# AVR16EB14 register map
Vendor: Atmel; File version: 1.0
CPU: other r0p0, little endian, no MPU, no FPU, 4 interrupt priority bits
Registers are 8-bit, read-write, reset 0x0 unless marked. A register's access mark holds for its fields unless they carry their own. Offsets are from the block's base; [hi:lo] are bit positions; {n}, {i} and the like mark numbered series; 'fields as' and 'values as' point back to an identical list.

## BOD — Bod interface
Base 0x008000A0
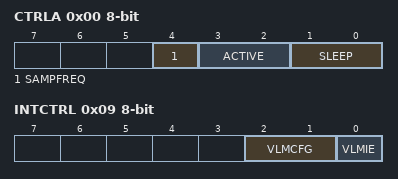
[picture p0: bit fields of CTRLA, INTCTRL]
0x00 CTRLA — Control A
  [4] SAMPFREQ ro — Sample frequency
    0=128HZ (Sampling frequency is 128 Hz); 1=32HZ (Sample frequency is 32 Hz)
  [3:2] ACTIVE ro — Operation in active mode
    0=DISABLE (Disabled); 1=ENABLED (Enabled in continuous mode); 2=SAMPLED (Enabled in sampled mode); 3=ENABLEWAIT (Enabled in continuous mode. Execution halted at wake-up until BOD is running)
  [1:0] SLEEP — Operation in sleep mode
    0=DISABLE (Disabled); 1=ENABLE (Enabled in continuous mode); 2=SAMPLE (Enabled in sampled mode)
0x01 CTRLB ro — Control B
  [2:0] LVL — Bod level
    0=BODLEVEL0 (BOD Disabled during normal operation); 1=BODLEVEL1 (1.9 V); 2=BODLEVEL2 (2.7 V); 3=BODLEVEL3 (4.5 V)
0x08 VLMCTRLA — Voltage level monitor Control
  [1:0] VLMLVL — voltage level monitor level
    0=OFF (VLM Disabled); 1=5ABOVE (VLM threshold 5% above BOD level); 2=15ABOVE (VLM threshold 15% above BOD level); 3=25ABOVE (VLM threshold 25% above BOD level)
0x09 INTCTRL — Voltage level monitor interrupt Control
  [2:1] VLMCFG — Configuration
    0=FALLING (VDD falls below VLM threshold); 1=RISING (VDD rises above VLM threshold); 2=BOTH (VDD crosses VLM threshold)
  [0] VLMIE — voltage level monitor interrrupt enable
0x0A INTFLAGS — Voltage level monitor interrupt Flags
  [0] VLMIF — Voltage level monitor interrupt flag
0x0B STATUS — Voltage level monitor status
  [0] VLMS ro
    0=ABOVE (The voltage is above the VLM threshold level); 1=BELOW (The voltage is below the VLM threshold level)

## BOOTROW
Base 0x00801100
0x00 BOOTROW

## USERROW
Base 0x00801200
Registers as BOOTROW (with BOOTROW read as USERROW).

## CCL — Configurable Custom Logic
Base 0x008001C0
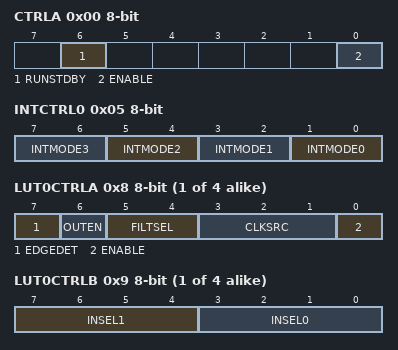
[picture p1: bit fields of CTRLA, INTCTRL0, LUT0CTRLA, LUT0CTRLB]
0x00 CTRLA — Control Register A
  [6] RUNSTDBY — Run in Standby
  [0] ENABLE
0x01 SEQCTRL0 — Sequential Control 0
  [3:0] SEQSEL — Sequential Selection
    0=DISABLE (Sequential logic disabled); 1=DFF (D FlipFlop); 2=JK (JK FlipFlop); 3=LATCH (D Latch); 4=RS (RS Latch)
0x02 SEQCTRL1 — Sequential Control 1
  fields as SEQCTRL0
0x05 INTCTRL0 — Interrupt Control 0
  [all] fields
    0=INTDISABLE (Interrupt disabled); 1=RISING (Sense rising edge); 2=FALLING (Sense falling edge); 3=BOTH (Sense both edges)
  [2n+1:2n] INTMODE{n} (n=0..3) — Interrupt Mode for LUT{n}
0x07 INTFLAGS — Interrupt Flags
  [3:0] INT — Interrupt Flag
{0x8+4i} LUT{i}CTRLA (i=0..3) — LUT {i} Control A
  [7] EDGEDET — Edge Detection Enable
    0=DIS (Edge detector is disabled); 1=EN (Edge detector is enabled)
  [6] OUTEN — Output Enable
  [5:4] FILTSEL — Filter Selection
    0=DISABLE (Filter disabled); 1=SYNCH (Synchronizer enabled); 2=FILTER (Filter enabled)
  [3:1] CLKSRC — Clock Source Selection
    0=CLKPER (Peripheral Clock); 1=IN2 (INSEL2 selection); 4=OSCHF (Internal High Frequency oscillator); 5=OSC32K (Internal 32.768 kHz oscillator); 6=OSC1K (Internal 32.768 kHz oscillator divided by 32); 7=PLL
  [0] ENABLE — LUT Enable
{0x9+4i} LUT{i}CTRLB (i=0..3) — LUT {i} Control B
  [7:4] INSEL1 — LUT Input 1 Source Selection
    0=MASK (Masked input); 1=FEEDBACK (Feedback input); 2=LINK (Output from LUT[n+1] as input source); 3=EVENTA (Event A as input source); 4=EVENTB (Event B as input source); 5=IN1 (IN1 input source); 6=AC1 (AC1 output input source); 7=USART0 (USART0 TxD input source); 8=SPI0 (SPI0 MOSI input source); 9=TCE0 (TCE0 WO1 input source); 10=TCB1 (TCB1 WO input source); 11=TCF0 (TCF0 WO1 input source); 12=WEX0 (Blanking input source)
  [3:0] INSEL0 — LUT Input 0 Source Selection
    0=MASK (Masked input); 1=FEEDBACK (Feedback input); 2=LINK (Output from LUT[n+1] as input source); 3=EVENTA (Event A as input source); 4=EVENTB (Event B as input source); 5=IN0 (IN0 input source); 6=AC0 (AC0 output input source); 7=USART0 (USART0 TxD input source); 8=SPI0 (SPI0 MOSI input source); 9=TCE0 (TCE0 WO0 input source); 10=TCB0 (TCB0 WO input source); 11=TCF0 (TCF0 WO0 input source); 12=WEX0 (Blanking input source)
{0xA+4i} LUT{i}CTRLC (i=0..3) — LUT {i} Control C
  [3:0] INSEL2 — LUT Input 2 Source Selection
    0=MASK (Masked input); 1=FEEDBACK (Feedback input); 2=LINK (Output from LUT[n+1] as input source); 3=EVENTA (Event A as input source); 4=EVENTB (Event B as input source); 5=IN2 (IN2 input source); 6=AC1 (AC1 output input source); 7=USART0 (USART0 TxD input source); 8=SPI0 (SPI0 SCK input source); 9=TCE0 (TCE0 WO2 input source); 10=TCB1 (TCB1 WO input source); 11=TCF0 (TCF0 WO0 input source); 12=WEX0 (Blanking input source)
{0xB+4i} TRUTH{i} (i=0..3)
  [7:0] TRUTH — Truth Table
